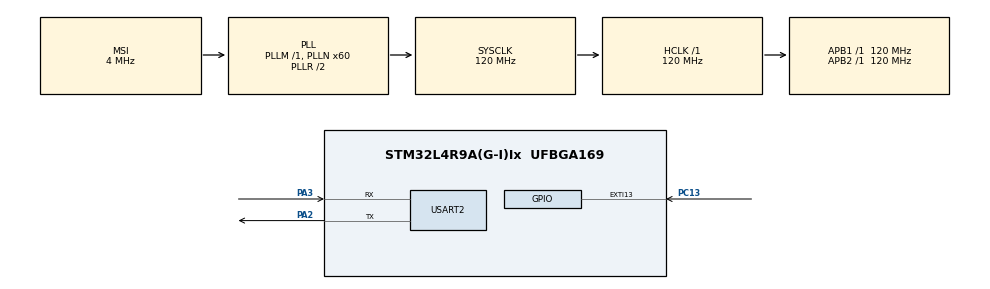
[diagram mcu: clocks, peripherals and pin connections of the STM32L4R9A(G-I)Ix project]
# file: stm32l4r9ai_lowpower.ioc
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Mcu.Family=STM32L4
Mcu.Name=STM32L4R9A(G-I)Ix
Mcu.Package=UFBGA169
NVIC.EXTI15_10_IRQn=true\:0\:0\:false\:false\:true\:true\:true
NVIC.PriorityGroup=NVIC_PRIORITYGROUP_4
NVIC.TIM1_TRG_COM_TIM17_IRQn=true\:0\:0\:false\:false\:true\:true\:true
NVIC.USART2_IRQn=true\:0\:0\:false\:false\:true\:true\:true
PA13\ (JTMS/SWDIO).Mode=Serial_Wire
PA13\ (JTMS/SWDIO).Signal=SYS_JTMS-SWDIO
PA14\ (JTCK/SWCLK).Mode=Serial_Wire
PA14\ (JTCK/SWCLK).Signal=SYS_JTCK-SWCLK
PA2.Mode=Asynchronous
PA2.Signal=USART2_TX
PA3.Mode=Asynchronous
PA3.Signal=USART2_RX
PC13.Signal=GPXTI13
ProjectManager.HeapSize=0x200
ProjectManager.StackSize=0x400
ProjectManager.TargetToolchain=EWARM V8
RCC.AHBFreq_Value=120000000
RCC.APB1Freq_Value=120000000
RCC.APB1TimFreq_Value=120000000
RCC.APB2Freq_Value=120000000
RCC.APB2TimFreq_Value=120000000
RCC.CortexFreq_Value=120000000
RCC.HCLKFreq_Value=120000000
RCC.HSE_VALUE=8000000
RCC.HSI48_VALUE=48000000
RCC.HSI_VALUE=16000000
RCC.LSE_VALUE=32768
RCC.MSI_VALUE=4000000
RCC.PLLN=60
RCC.SYSCLKFreq_VALUE=120000000
RCC.SYSCLKSource=RCC_SYSCLKSOURCE_PLLCLK
RCC.VCOOutputFreq_Value=240000000
TIM17.Period=1000
TIM17.Prescaler=1200
USART2.VirtualMode-Asynchronous=VM_ASYNC
VP_TIM17_VS_ClockSourceINT.Mode=Enable_Timer
board=custom

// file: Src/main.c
/* USER CODE BEGIN Header */
/**
  ******************************************************************************
  * @file           : main.c
  * @brief          : Main program body
  ******************************************************************************
  * @attention
  *
  * <h2><center>&copy; Copyright (c) 2019 STMicroelectronics.
  * All rights reserved.</center></h2>
  *
  * This software component is licensed by ST under BSD 3-Clause license,
  * the "License"; You may not use this file except in compliance with the
  * License. You may obtain a copy of the License at:
  *                        opensource.org/licenses/BSD-3-Clause
  *
  ******************************************************************************
  */
/* USER CODE END Header */

#include "main.h"
#include "tim.h"
#include "usart.h"
#include "gpio.h"

/* USER CODE BEGIN Includes */
#include <stdio.h>
/* USER CODE END Includes */

/* USER CODE BEGIN PM */
#define PUTCHAR_PROTOTYPE int fputc(int ch, FILE *f)
/* USER CODE END PM */

/* USER CODE BEGIN PV */
static uint8_t uart2_rx_buffer[1];
/* USER CODE END PV */

void SystemClock_Config(void);

/* USER CODE BEGIN 0 */
PUTCHAR_PROTOTYPE
{
  /* Place your implementation of fputc here */
  /* e.g. write a character to the USART1 and Loop until the end of transmission */
  HAL_UART_Transmit(&huart2, (uint8_t *)&ch, 1, 0xFFFF);

  return ch;
}
/* USER CODE END 0 */

int main(void)
{

  /* MCU Configuration--------------------------------------------------------*/

  /* Reset of all peripherals, Initializes the Flash interface and the Systick. */
  HAL_Init();

  /* Configure the system clock */
  SystemClock_Config();

  /* Initialize all configured peripherals */
  MX_GPIO_Init();
  MX_TIM17_Init();
  MX_USART2_UART_Init();
  /* USER CODE BEGIN 2 */
  printf("** hello world ** \n\r");
  /* USER CODE END 2 */

  /* Infinite loop */
  /* USER CODE BEGIN WHILE */
  int i = 0;
  while (1)
  {
    i++;
    printf("%d \n\r", i);
    HAL_Delay(1000);

    if((i%5) == 0)
    {
      if((i%10) == 0)
      {
        printf("** into stop2 \n\r");
        HAL_UART_Receive_IT(&huart2, uart2_rx_buffer, 1);
        HAL_PWREx_EnterSTOP2Mode(PWR_STOPENTRY_WFI);
        SystemClock_Config();
      }
      else
      {
        printf("** into sleep \n\r");
        HAL_UART_Receive_IT(&huart2, uart2_rx_buffer, 1);
        HAL_SuspendTick();
        HAL_PWR_EnterSLEEPMode(PWR_MAINREGULATOR_ON, PWR_SLEEPENTRY_WFI);
        HAL_ResumeTick();
      }
    }
    /* USER CODE END WHILE */

  }
}

void SystemClock_Config(void)
{
  RCC_OscInitTypeDef RCC_OscInitStruct = {0};
  RCC_ClkInitTypeDef RCC_ClkInitStruct = {0};
  RCC_PeriphCLKInitTypeDef PeriphClkInit = {0};

  /** Configure the main internal regulator output voltage
  */
  if (HAL_PWREx_ControlVoltageScaling(PWR_REGULATOR_VOLTAGE_SCALE1_BOOST) != HAL_OK)
  {
    Error_Handler();
  }
  /** Initializes the CPU, AHB and APB busses clocks
  */
  RCC_OscInitStruct.OscillatorType = RCC_OSCILLATORTYPE_MSI;
  RCC_OscInitStruct.MSIState = RCC_MSI_ON;
  RCC_OscInitStruct.MSICalibrationValue = 0;
  RCC_OscInitStruct.MSIClockRange = RCC_MSIRANGE_6;
  RCC_OscInitStruct.PLL.PLLState = RCC_PLL_ON;
  RCC_OscInitStruct.PLL.PLLSource = RCC_PLLSOURCE_MSI;
  RCC_OscInitStruct.PLL.PLLM = 1;
  RCC_OscInitStruct.PLL.PLLN = 60;
  RCC_OscInitStruct.PLL.PLLP = RCC_PLLP_DIV2;
  RCC_OscInitStruct.PLL.PLLQ = RCC_PLLQ_DIV2;
  RCC_OscInitStruct.PLL.PLLR = RCC_PLLR_DIV2;
  if (HAL_RCC_OscConfig(&RCC_OscInitStruct) != HAL_OK)
  {
    Error_Handler();
  }
  /** Initializes the CPU, AHB and APB busses clocks
  */
  RCC_ClkInitStruct.ClockType = RCC_CLOCKTYPE_HCLK|RCC_CLOCKTYPE_SYSCLK
                              |RCC_CLOCKTYPE_PCLK1|RCC_CLOCKTYPE_PCLK2;
  RCC_ClkInitStruct.SYSCLKSource = RCC_SYSCLKSOURCE_PLLCLK;
  RCC_ClkInitStruct.AHBCLKDivider = RCC_SYSCLK_DIV1;
  RCC_ClkInitStruct.APB1CLKDivider = RCC_HCLK_DIV1;
  RCC_ClkInitStruct.APB2CLKDivider = RCC_HCLK_DIV1;

  if (HAL_RCC_ClockConfig(&RCC_ClkInitStruct, FLASH_LATENCY_5) != HAL_OK)
  {
    Error_Handler();
  }
  PeriphClkInit.PeriphClockSelection = RCC_PERIPHCLK_USART2;
  PeriphClkInit.Usart2ClockSelection = RCC_USART2CLKSOURCE_PCLK1;
  if (HAL_RCCEx_PeriphCLKConfig(&PeriphClkInit) != HAL_OK)
  {
    Error_Handler();
  }
}

void Error_Handler(void)
{
}

/************************ (C) COPYRIGHT STMicroelectronics *****END OF FILE****/
